# MM32F013x register map
File version: 1.01
CPU: CM0 r0p0, little endian, no MPU, no FPU, 2 interrupt priority bits
Registers are 32-bit, read-write, reset 0x0 unless marked. A register's access mark holds for its fields unless they carry their own. Offsets are from the block's base; [hi:lo] are bit positions; {n}, {i} and the like mark numbered series; 'fields as' and 'values as' point back to an identical list.

## DBG — Debug support
Base 0x40013400
0x00 IDCODE ro
  [31:0] DEV_ID — Device identifier
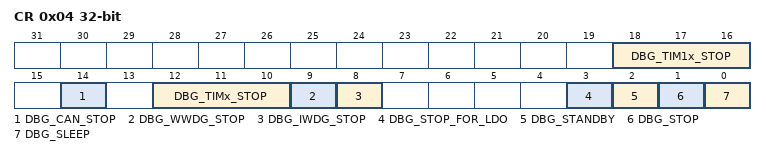
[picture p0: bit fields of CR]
0x04 CR wo — Control Register
  [18:16] DBG_TIM1x_STOP — TIMx counter stopped when core is halted (x = 16,17,14)
  [14] DBG_CAN_STOP — CAN stopped when core is halted
  [12:10] DBG_TIMx_STOP — TIMx counter stopped when core is halted (x = 3,2,1)
  [9] DBG_WWDG_STOP — Debug window watchdog when core is halted
  [8] DBG_IWDG_STOP — Debug independent watchdog stopped when core is stopped
  [3] DBG_STOP_FOR_LDO — Debug Stop Ldo
  [2] DBG_STANDBY — Debug Standby mode
  [1] DBG_STOP — Debug Stop mode
  [0] DBG_SLEEP — Debug Sleep mode

## DEVICE
Base 0x1FFFF7E8
0x00 UID1 ro — Configuration register
  [31:0] U_ID — 31:0 unique ID bits
0x04 UID2 ro — Configuration register
  [31:0] U_ID — 63:32 unique ID bits
0x08 UID3 ro — Configuration register
  [31:0] U_ID — 95:64 unique ID bits

## DMA1 — Direct Momory Accessuart
Base 0x40020000
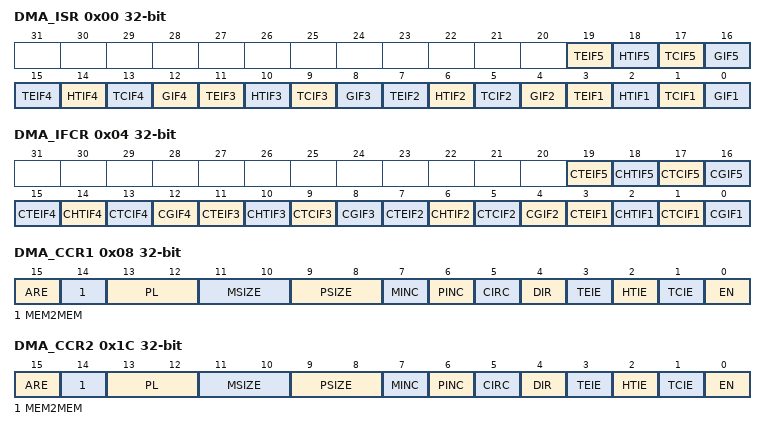
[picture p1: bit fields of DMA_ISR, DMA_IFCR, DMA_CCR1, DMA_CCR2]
0x00 DMA_ISR ro — DMA interrupt status register
  [4n-1] TEIF{n} (n=1..5) — channel {n} transfer error flag
  [4n-2] HTIF{n} (n=1..5) — channel {n} half transfer flag
  [4n-3] TCIF{n} (n=1..5) — channel {n} transfer complete flag
  [4n-4] GIF{n} (n=1..5) — channel {n} global interrupt flag
0x04 DMA_IFCR wo — DMA interrupt flag clear reigster
  [4n-1] CTEIF{n} (n=1..5) — channel {n} transfer error clear
  [4n-2] CHTIF{n} (n=1..5) — channel {n} half transfer clear
  [4n-3] CTCIF{n} (n=1..5) — channel {n} transfer complete clear
  [4n-4] CGIF{n} (n=1..5) — channel {n} global interrupt clear
0x08 DMA_CCR1 — DMA channel 1 configuration reigster
  [15] ARE — Auto Reload
  [14] MEM2MEM — Memory to memory mode
  [13:12] PL — Channel priority level
  [11:10] MSIZE — Memory size
  [9:8] PSIZE — Peripheral size
  [7] MINC — Memory increment mode
  [6] PINC — Peripheral increment mode
  [5] CIRC — Circular mode
  [4] DIR — Data transfer direction
  [3] TEIE — Transfer error interrupt enable
  [2] HTIE — Half transfer interrupt enable
  [1] TCIE — Transfer complete interrupt enable
  [0] EN — Channel enable
0x0C DMA_CNDTR1 — DMA channel 1 number of data register
  [15:0] NDT — Number of data to transfer
0x10 DMA_CPAR1 — DMA channel 1 peripheral address register
  [31:0] PA — Peripheral address
{0x0+0x14*i} DMA_CMAR{i} (i=1..5) — DMA channel 1 memory address register
  [31:0] MA — Memory address
0x1C DMA_CCR2 — DMA channel 1 configuration reigster
  fields as DMA_CCR1
0x20 DMA_CNDTR2 — DMA channel 1 number of data register
  [15:0] NDT — Number of data to transfer
0x24 DMA_CPAR2 — DMA channel 1 peripheral address register
  [31:0] PA — Peripheral address
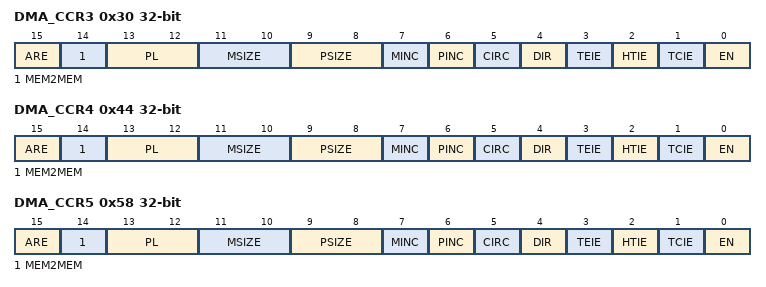
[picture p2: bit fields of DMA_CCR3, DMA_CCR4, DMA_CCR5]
0x30 DMA_CCR3 — DMA channel 1 configuration reigster
  fields as DMA_CCR1
0x34 DMA_CNDTR3 — DMA channel 1 number of data register
  [15:0] NDT — Number of data to transfer
0x38 DMA_CPAR3 — DMA channel 1 peripheral address register
  [31:0] PA — Peripheral address
0x44 DMA_CCR4 — DMA channel 1 configuration reigster
  fields as DMA_CCR1
0x48 DMA_CNDTR4 — DMA channel 1 number of data register
  [15:0] NDT — Number of data to transfer
0x4C DMA_CPAR4 — DMA channel 1 peripheral address register
  [31:0] PA — Peripheral address
0x58 DMA_CCR5 — DMA channel 1 configuration reigster
  fields as DMA_CCR1
0x5C DMA_CNDTR5 — DMA channel 1 number of data register
  [15:0] NDT — Number of data to transfer
0x60 DMA_CPAR5 — DMA channel 1 peripheral address register
  [31:0] PA — Peripheral address

## EXTI — External interrupt/event controller
Base 0x40010000
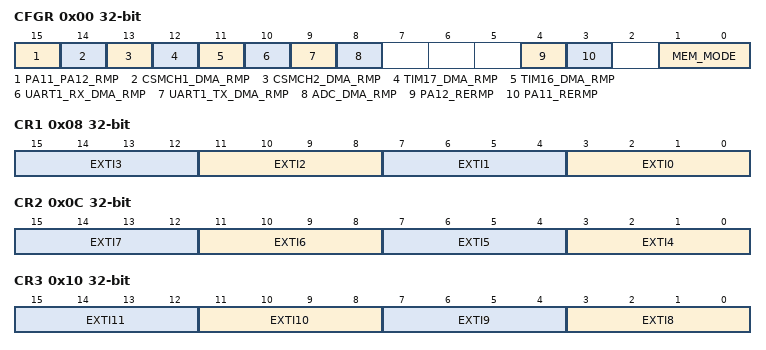
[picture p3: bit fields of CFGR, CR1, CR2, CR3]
0x00 CFGR — Configuration register
  [15] PA11_PA12_RMP — PA11 PA12 remap
  [14] CSMCH1_DMA_RMP — CSMCH1 DMA remap
  [13] CSMCH2_DMA_RMP — CSMCH2 DMA remap
  [12] TIM17_DMA_RMP — Timer 17 DMA remap
  [11] TIM16_DMA_RMP — Timer 16 DMA remap
  [10] UART1_RX_DMA_RMP — UART1 RX DMA remap
  [9] UART1_TX_DMA_RMP — UART1 TX DMA remap
  [8] ADC_DMA_RMP — ADC DMA remap
  [4] PA12_RERMP — PA12 DMA remap
  [3] PA11_RERMP — PA11 DMA remap
  [1:0] MEM_MODE — EXTI_Memory Remap Config
0x08 CR1 — External interrupt configuration register 1
  [4n+3:4n] EXTI{n} (n=0..3) — EXTI {n} configuration
0x0C CR2 — External interrupt configuration register 2
  [4n-13:4n-16] EXTI{n} (n=4..7) — EXTI {n} configuration
0x10 CR3 — External interrupt configuration register 3
  [4n-29:4n-32] EXTI{n} (n=8..11) — EXTI {n} configuration
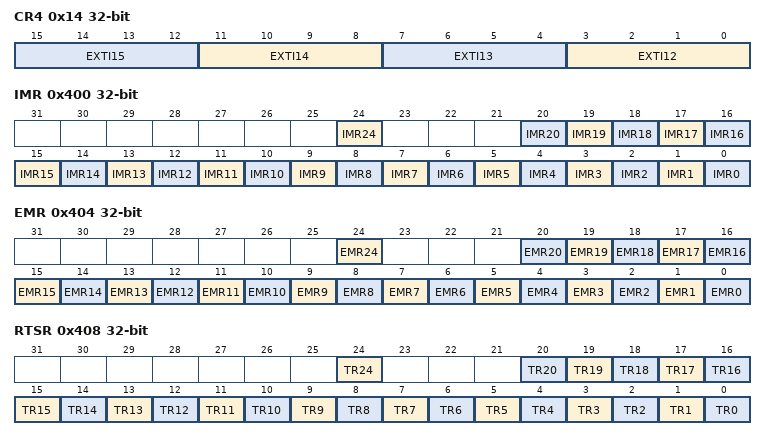
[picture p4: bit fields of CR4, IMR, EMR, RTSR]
0x14 CR4 — External interrupt configuration register 4
  [4n-45:4n-48] EXTI{n} (n=12..15) — EXTI {n} configuration
0x18 PADHYS — PAD configuration register
  [16] I2C1_mode_sel — I2C1 mode selection
0x400 IMR — Interrupt mask register
  [24] IMR24 — Interrupt Mask on line 24
  [n] IMR{n} (n=0..20) — Interrupt Mask on line {n}
0x404 EMR — Event mask register
  [24] EMR24 — Event Mask on line 24
  [n] EMR{n} (n=0..20) — Event Mask on line {n}
0x408 RTSR — Rising trigger selection register
  [24] TR24 — Rising trigger event configuration bit of line 24
  [n] TR{n} (n=0..20) — Rising trigger event configuration bit of line {n}
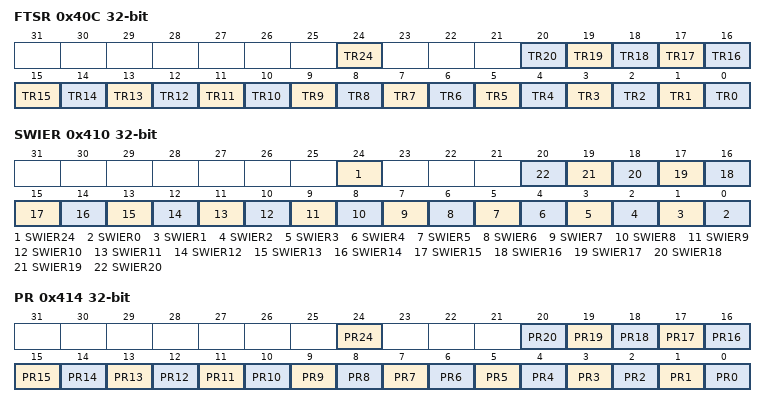
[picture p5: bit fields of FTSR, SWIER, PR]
0x40C FTSR — Falling trigger selection register
  [24] TR24 — Falling trigger event configuration bit of line 24
  [n] TR{n} (n=0..20) — Falling trigger event configuration bit of line {n}
0x410 SWIER — Software interrupt event register
  [24] SWIER24 — Software interrupt on line 24
  [n] SWIER{n} (n=0..20) — Software interrupt on line {n}
0x414 PR — Pending register
  [24] PR24 — Pending bit
  [n] PR{n} (n=0..20) — Pending bit
